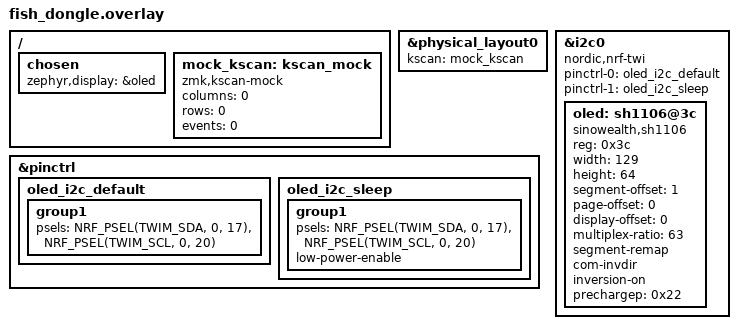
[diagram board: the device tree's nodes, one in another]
// Eyelash ドングル（nice!nano + 1.3インチ SH1106 OLED）を親機にするための設定
// 左右のおさかなは両方とも子機（peripheral）になる

#include "fish.dtsi"

/ {
    chosen {
        zephyr,display = &oled;
    };

    // ドングルにはキーが無いので、ダミーのkscanを使う
    mock_kscan: kscan_mock {
        compatible = "zmk,kscan-mock";
        columns = <0>;
        rows = <0>;
        events = <0>;
    };
};

&physical_layout0 {
    kscan = <&mock_kscan>;
};

// 左右用のGPIOマトリクスはドングルでは使わない
/delete-node/ &kscan0;

// OLED: SDA = P0.17, SCL = P0.20
&pinctrl {
    oled_i2c_default: oled_i2c_default {
        group1 {
            psels = <NRF_PSEL(TWIM_SDA, 0, 17)>,
                    <NRF_PSEL(TWIM_SCL, 0, 20)>;
        };
    };

    oled_i2c_sleep: oled_i2c_sleep {
        group1 {
            psels = <NRF_PSEL(TWIM_SDA, 0, 17)>,
                    <NRF_PSEL(TWIM_SCL, 0, 20)>;
            low-power-enable;
        };
    };
};

&i2c0 {
    status = "okay";
    compatible = "nordic,nrf-twi";
    pinctrl-0 = <&oled_i2c_default>;
    pinctrl-1 = <&oled_i2c_sleep>;
    pinctrl-names = "default", "sleep";

    oled: sh1106@3c {
        compatible = "sinowealth,sh1106";
        reg = <0x3c>;
        // Eyelash ドングル公式設定（zmk-corne-dongle）と同じ値
        width = <129>;
        height = <64>;
        segment-offset = <1>;
        page-offset = <0>;
        display-offset = <0>;
        multiplex-ratio = <63>;
        segment-remap;
        com-invdir;
        inversion-on;
        prechargep = <0x22>;
    };
};
